# ioADuCM4050 register map
Registers are 16-bit, access not given, no defined reset value unless marked. A register's access mark holds for its fields unless they carry their own. Addresses are absolute; registers are grouped by the start of their names; [hi:lo] are bit positions; {n}, {i} and the like mark numbered series.

## FLCC0
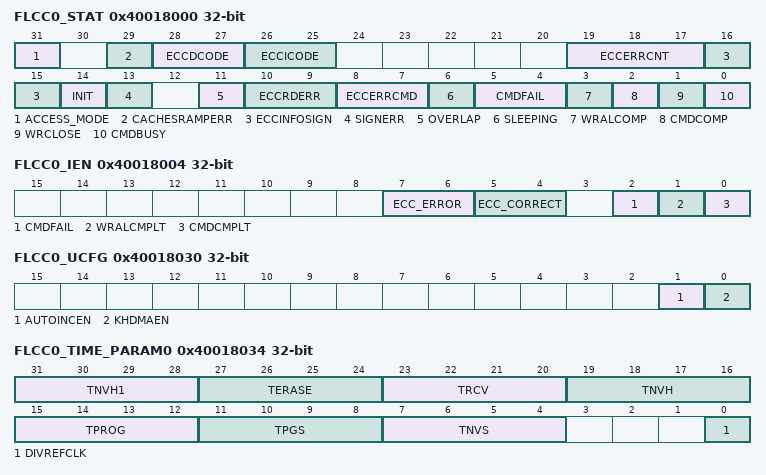
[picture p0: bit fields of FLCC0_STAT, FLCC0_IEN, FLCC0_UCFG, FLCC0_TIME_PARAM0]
0x40018000 FLCC0_STAT 32-bit
  [31] ACCESS_MODE, [29] CACHESRAMPERR, [28:27] ECCDCODE, [26:25] ECCICODE, [19:17] ECCERRCNT, [16:15] ECCINFOSIGN, [14] INIT, [13] SIGNERR, [11] OVERLAP, [10:9] ECCRDERR, [8:7] ECCERRCMD, [6] SLEEPING, [5:4] CMDFAIL, [3] WRALCOMP, [2] CMDCOMP, [1] WRCLOSE, [0] CMDBUSY
0x40018004 FLCC0_IEN 32-bit
  [7:6] ECC_ERROR, [5:4] ECC_CORRECT, [2] CMDFAIL, [1] WRALCMPLT, [0] CMDCMPLT
0x40018008 FLCC0_CMD 32-bit
  [3:0] VALUE
0x4001800C FLCC0_KH_ADDR 32-bit
  [19:3] VALUE
0x40018010 FLCC0_KH_DATA0 32-bit
0x40018014 FLCC0_KH_DATA1 32-bit
0x40018018 FLCC0_PAGE_ADDR0 32-bit
  [19:10] VALUE
0x4001801C FLCC0_PAGE_ADDR1 32-bit
  [19:10] VALUE
0x40018020 FLCC0_KEY 32-bit
0x40018024 FLCC0_WR_ABORT_ADDR 32-bit
0x40018028 FLCC0_WRPROT 32-bit
0x4001802C FLCC0_SIGNATURE 32-bit
0x40018030 FLCC0_UCFG 32-bit
  [1] AUTOINCEN, [0] KHDMAEN
0x40018034 FLCC0_TIME_PARAM0 32-bit
  [31:28] TNVH1, [27:24] TERASE, [23:20] TRCV, [19:16] TNVH, [15:12] TPROG, [11:8] TPGS, [7:4] TNVS, [0] DIVREFCLK
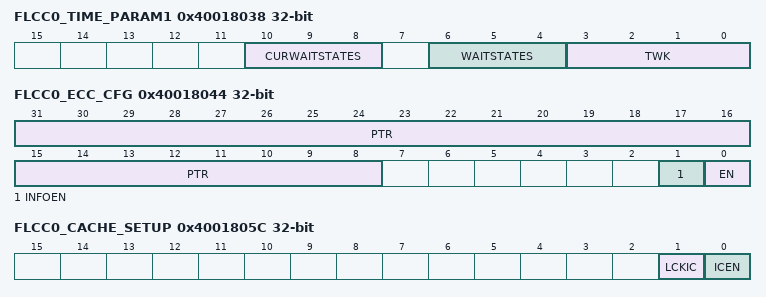
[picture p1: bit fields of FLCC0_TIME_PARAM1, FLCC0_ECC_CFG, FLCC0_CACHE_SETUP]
0x40018038 FLCC0_TIME_PARAM1 32-bit
  [10:8] CURWAITSTATES, [6:4] WAITSTATES, [3:0] TWK
0x4001803C FLCC0_ABORT_EN_LO 32-bit
0x40018040 FLCC0_ABORT_EN_HI 32-bit
0x40018044 FLCC0_ECC_CFG 32-bit
  [31:8] PTR, [1] INFOEN, [0] EN
0x40018048 FLCC0_ECC_ADDR 32-bit
  [19:0] VALUE
0x40018050 FLCC0_POR_SEC 32-bit
  [0] SECURE
0x40018054 FLCC0_VOL_CFG 32-bit
  [0] INFO_REMAP
0x40018058 FLCC0_CACHE_STAT 32-bit
  [0] ICEN
0x4001805C FLCC0_CACHE_SETUP 32-bit
  [1] LCKIC, [0] ICEN
0x40018060 FLCC0_CACHE_KEY 32-bit

## GPIO0
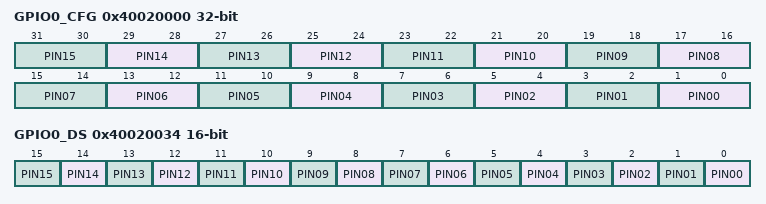
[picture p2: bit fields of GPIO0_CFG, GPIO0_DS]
0x40020000 GPIO0_CFG 32-bit
  [2n+1:2n] PIN{n:02} (n=0..15)
0x40020004 GPIO0_OEN
0x40020008 GPIO0_PE
0x4002000C GPIO0_IEN
0x40020010 GPIO0_IN
0x40020014 GPIO0_OUT
0x40020018 GPIO0_SET
0x4002001C GPIO0_CLR
0x40020020 GPIO0_TGL
0x40020024 GPIO0_POL
0x40020028 GPIO0_IENA
0x4002002C GPIO0_IENB
0x40020030 GPIO0_INT
0x40020034 GPIO0_DS
  [n] PIN{n:02} (n=0..15)

## GPIO1
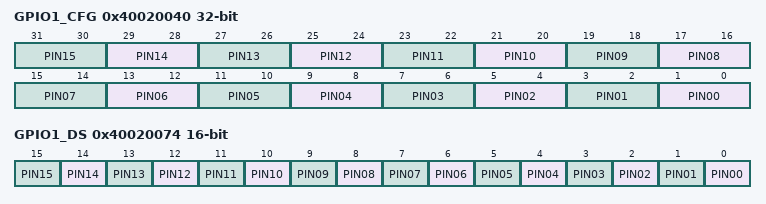
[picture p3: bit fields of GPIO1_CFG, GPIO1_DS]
0x40020040 GPIO1_CFG 32-bit
  [2n+1:2n] PIN{n:02} (n=0..15)
0x40020044 GPIO1_OEN
0x40020048 GPIO1_PE
0x4002004C GPIO1_IEN
0x40020050 GPIO1_IN
0x40020054 GPIO1_OUT
0x40020058 GPIO1_SET
0x4002005C GPIO1_CLR
0x40020060 GPIO1_TGL
0x40020064 GPIO1_POL
0x40020068 GPIO1_IENA
0x4002006C GPIO1_IENB
0x40020070 GPIO1_INT
0x40020074 GPIO1_DS
  [n] PIN{n:02} (n=0..15)

## GPIO2
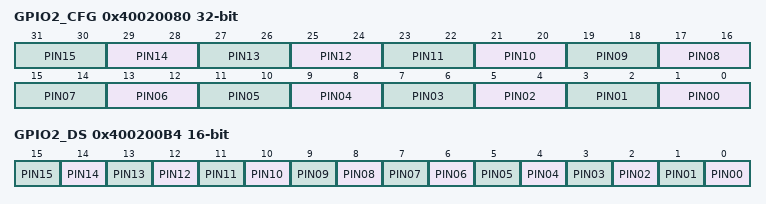
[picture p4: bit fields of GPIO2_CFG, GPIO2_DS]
0x40020080 GPIO2_CFG 32-bit
  [2n+1:2n] PIN{n:02} (n=0..15)
0x40020084 GPIO2_OEN
0x40020088 GPIO2_PE
0x4002008C GPIO2_IEN
0x40020090 GPIO2_IN
0x40020094 GPIO2_OUT
0x40020098 GPIO2_SET
0x4002009C GPIO2_CLR
0x400200A0 GPIO2_TGL
0x400200A4 GPIO2_POL
0x400200A8 GPIO2_IENA
0x400200AC GPIO2_IENB
0x400200B0 GPIO2_INT
0x400200B4 GPIO2_DS
  [n] PIN{n:02} (n=0..15)

## GPIO3
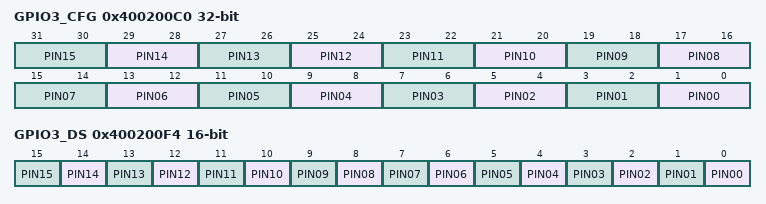
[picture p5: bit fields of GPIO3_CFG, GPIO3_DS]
0x400200C0 GPIO3_CFG 32-bit
  [2n+1:2n] PIN{n:02} (n=0..15)
0x400200C4 GPIO3_OEN
0x400200C8 GPIO3_PE
0x400200CC GPIO3_IEN
0x400200D0 GPIO3_IN
0x400200D4 GPIO3_OUT
0x400200D8 GPIO3_SET
0x400200DC GPIO3_CLR
0x400200E0 GPIO3_TGL
0x400200E4 GPIO3_POL
0x400200E8 GPIO3_IENA
0x400200EC GPIO3_IENB
0x400200F0 GPIO3_INT
0x400200F4 GPIO3_DS
  [n] PIN{n:02} (n=0..15)

## SPORT0
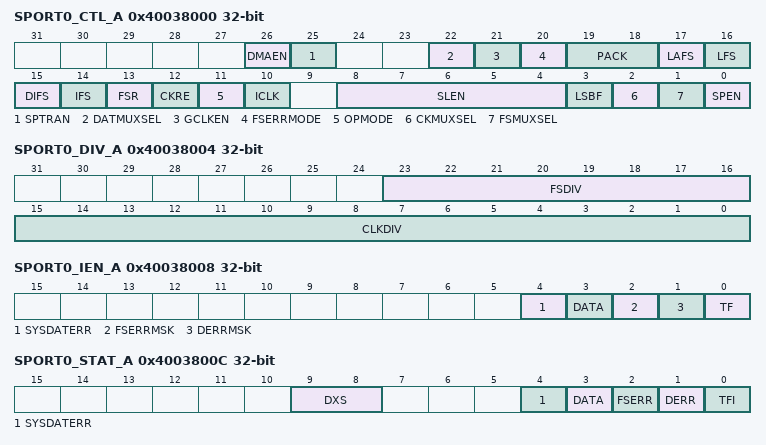
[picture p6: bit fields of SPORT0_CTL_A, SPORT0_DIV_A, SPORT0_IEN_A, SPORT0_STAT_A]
0x40038000 SPORT0_CTL_A 32-bit
  [26] DMAEN, [25] SPTRAN, [22] DATMUXSEL, [21] GCLKEN, [20] FSERRMODE, [19:18] PACK, [17] LAFS, [16] LFS, [15] DIFS, [14] IFS, [13] FSR, [12] CKRE, [11] OPMODE, [10] ICLK, [8:4] SLEN, [3] LSBF, [2] CKMUXSEL, [1] FSMUXSEL, [0] SPEN
0x40038004 SPORT0_DIV_A 32-bit
  [23:16] FSDIV, [15:0] CLKDIV
0x40038008 SPORT0_IEN_A 32-bit
  [4] SYSDATERR, [3] DATA, [2] FSERRMSK, [1] DERRMSK, [0] TF
0x4003800C SPORT0_STAT_A 32-bit
  [9:8] DXS, [4] SYSDATERR, [3] DATA, [2] FSERR, [1] DERR, [0] TFI
0x40038010 SPORT0_NUMTRAN_A 32-bit
  [11:0] VALUE
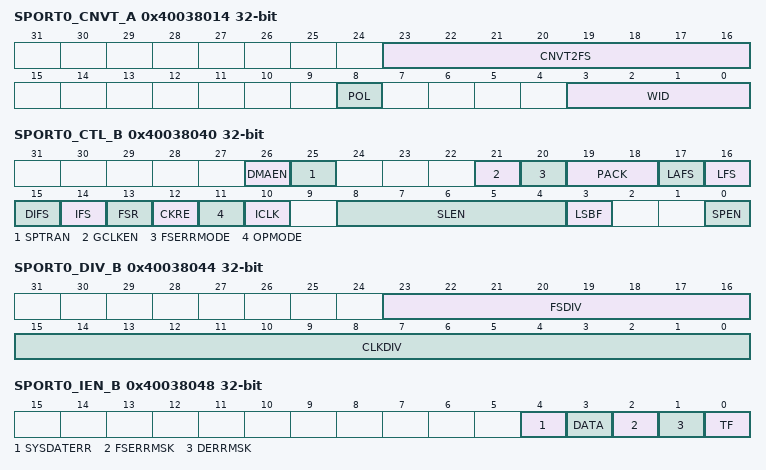
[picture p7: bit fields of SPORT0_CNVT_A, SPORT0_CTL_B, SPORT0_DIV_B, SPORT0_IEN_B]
0x40038014 SPORT0_CNVT_A 32-bit
  [23:16] CNVT2FS, [8] POL, [3:0] WID
0x40038020 SPORT0_TX_A 32-bit
0x40038028 SPORT0_RX_A 32-bit
0x40038040 SPORT0_CTL_B 32-bit
  [26] DMAEN, [25] SPTRAN, [21] GCLKEN, [20] FSERRMODE, [19:18] PACK, [17] LAFS, [16] LFS, [15] DIFS, [14] IFS, [13] FSR, [12] CKRE, [11] OPMODE, [10] ICLK, [8:4] SLEN, [3] LSBF, [0] SPEN
0x40038044 SPORT0_DIV_B 32-bit
  [23:16] FSDIV, [15:0] CLKDIV
0x40038048 SPORT0_IEN_B 32-bit
  [4] SYSDATERR, [3] DATA, [2] FSERRMSK, [1] DERRMSK, [0] TF
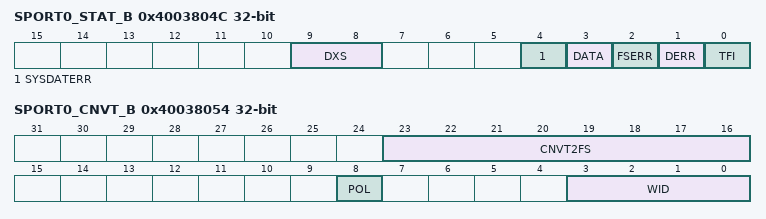
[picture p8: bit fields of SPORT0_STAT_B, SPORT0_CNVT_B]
0x4003804C SPORT0_STAT_B 32-bit
  [9:8] DXS, [4] SYSDATERR, [3] DATA, [2] FSERR, [1] DERR, [0] TFI
0x40038050 SPORT0_NUMTRAN_B 32-bit
  [11:0] VALUE
0x40038054 SPORT0_CNVT_B 32-bit
  [23:16] CNVT2FS, [8] POL, [3:0] WID
0x40038060 SPORT0_TX_B 32-bit
0x40038068 SPORT0_RX_B 32-bit
